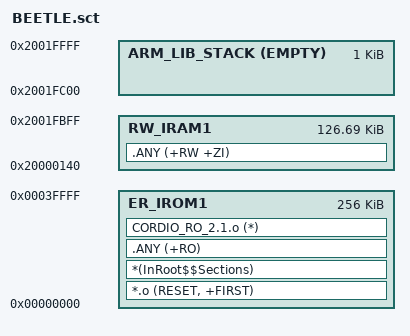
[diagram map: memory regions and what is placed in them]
#! armcc -E;
/*
; * BEETLE CMSIS Library
; */
;/*
; * Copyright (c) 2009-2016 ARM Limited. All rights reserved.
; *
; * SPDX-License-Identifier: Apache-2.0
; *
; * Licensed under the Apache License, Version 2.0 (the License); you may
; * not use this file except in compliance with the License.
; * You may obtain a copy of the License at
; *
; * http://www.apache.org/licenses/LICENSE-2.0
; *
; * Unless required by applicable law or agreed to in writing, software
; * distributed under the License is distributed on an AS IS BASIS, WITHOUT
; * WARRANTIES OR CONDITIONS OF ANY KIND, either express or implied.
; * See the License for the specific language governing permissions and
; * limitations under the License.
; */
; *************************************************************
; *** Scatter-Loading Description File                      ***
; *************************************************************

#if !defined(MBED_BOOT_STACK_SIZE)
  #define MBED_BOOT_STACK_SIZE 0x400
#endif

#define Stack_Size MBED_BOOT_STACK_SIZE

LR_IROM1 0x00000000 0x00040000  {    ; load region size_region
  ER_IROM1 0x00000000 0x00040000  {  ; load address = execution address
   *.o (RESET, +FIRST)
   *(InRoot$$Sections)
   .ANY (+RO)
   CORDIO_RO_2.1.o (*)
  }
  ; Total: 80 vectors = 320 bytes (0x140) to be reserved in RAM
  RW_IRAM1 (0x20000000+0x140) (0x20000-0x140-Stack_Size)  {  ; RW data
   .ANY (+RW +ZI)
  }
  
  ARM_LIB_STACK (0x20000000+0x20000) EMPTY -Stack_Size { ; stack
  }
}
